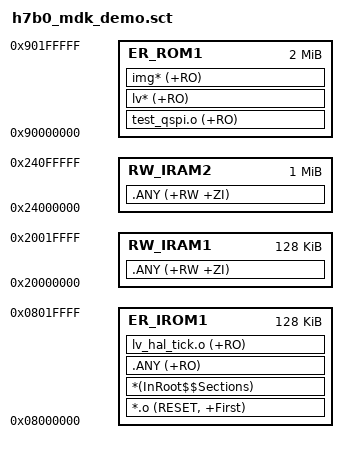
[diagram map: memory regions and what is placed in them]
; *************************************************************
; *** Scatter-Loading Description File generated by uVision ***
; *************************************************************
LR_ROM1 0x90000000 0x00200000  {
  ER_ROM1 0x90000000 0x00200000  {  ; load address = execution address
   test_qspi.o (+RO)
   lv* (+RO)
   img* (+RO)
  }
}

LR_IROM1 0x08000000 0x00020000  {    ; load region size_region
  ER_IROM1 0x08000000 0x00020000  {  ; load address = execution address
   *.o (RESET, +First)
   *(InRoot$$Sections)
   .ANY (+RO)
   lv_hal_tick.o (+RO)
  }
  RW_IRAM1 0x20000000 0x00020000  {  ; RW data
   .ANY (+RW +ZI)
  }
  RW_IRAM2 0x24000000 0x00100000  {
   .ANY (+RW +ZI)
  }
}


